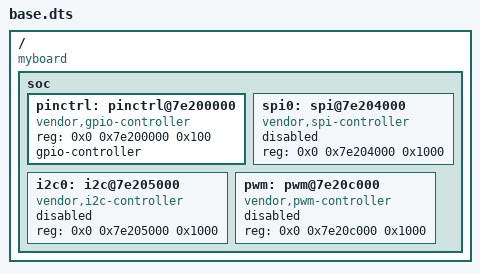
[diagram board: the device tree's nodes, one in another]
/dts-v1/;

/ {
    compatible = "myboard";
    #address-cells = <2>;
    #size-cells = <1>;

    soc {
        #address-cells = <2>;
        #size-cells = <1>;
        ranges;

        pinctrl: pinctrl@7e200000 {
            compatible = "vendor,gpio-controller";
            reg = <0x0 0x7e200000 0x100>;
            gpio-controller;
            #gpio-cells = <2>;
        };

        spi0: spi@7e204000 {
            compatible = "vendor,spi-controller";
            reg = <0x0 0x7e204000 0x1000>;
            status = "disabled";
            #address-cells = <1>;
            #size-cells = <0>;
        };

        i2c0: i2c@7e205000 {
            compatible = "vendor,i2c-controller";
            reg = <0x0 0x7e205000 0x1000>;
            status = "disabled";
            #address-cells = <1>;
            #size-cells = <0>;
        };

        pwm: pwm@7e20c000 {
            compatible = "vendor,pwm-controller";
            reg = <0x0 0x7e20c000 0x1000>;
            status = "disabled";
            #pwm-cells = <2>;
        };
    };
};
